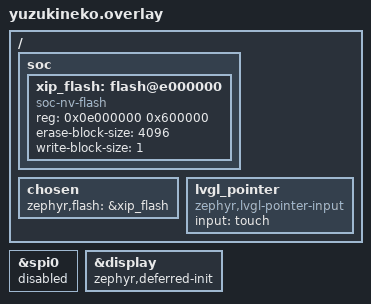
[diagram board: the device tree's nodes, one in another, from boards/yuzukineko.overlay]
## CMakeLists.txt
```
# SPDX-License-Identifier: Apache-2.0

cmake_minimum_required(VERSION 3.20.0)
# the emulator modules sit next to this application
list(APPEND ZEPHYR_EXTRA_MODULES ${CMAKE_CURRENT_SOURCE_DIR}/../mgba ${CMAKE_CURRENT_SOURCE_DIR}/../nes
	${CMAKE_CURRENT_SOURCE_DIR}/../aic8800)

find_package(Zephyr REQUIRED HINTS $ENV{ZEPHYR_BASE})
project(mp5_player)

# sources include each other as "core/cfg.h"; LVGL includes lv_rvv.h from its blend sources
zephyr_include_directories(src src/gfx)

# the start steps and the registries of the user interface are read only records that the
# modules register; the linker collects them
zephyr_linker_sources(SECTIONS src/core/sections-rom.ld)
zephyr_linker_sources(SECTIONS src/ui/sections-rom.ld)

target_sources(app PRIVATE src/main.c)
add_subdirectory(src/core)
add_subdirectory(src/ui)
add_subdirectory(src/gfx)
add_subdirectory(src/debug)
add_subdirectory(src/features/home)
add_subdirectory(src/features/files)
add_subdirectory(src/features/settings)
add_subdirectory(src/features/video)
add_subdirectory(src/features/photos)
add_subdirectory(src/features/games)
add_subdirectory(src/features/usbdisplay)
add_subdirectory(src/features/net)
```

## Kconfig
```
# SPDX-License-Identifier: Apache-2.0

mainmenu "MP5 player"

rsource "src/core/Kconfig"
rsource "src/gfx/Kconfig"
rsource "src/features/*/Kconfig"
rsource "src/debug/Kconfig"

source "Kconfig.zephyr"
```

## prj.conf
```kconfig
# the whole image runs from the flash window of the SPIF controller (see boards/yuzukineko.overlay)
CONFIG_XIP=y

CONFIG_SDHC=y
CONFIG_DISK_ACCESS=y
CONFIG_DISK_DRIVER_SDMMC=y
CONFIG_FILE_SYSTEM=y
CONFIG_FAT_FILESYSTEM_ELM=y
CONFIG_FS_FATFS_EXFAT=y
CONFIG_FS_FATFS_LFN=y
CONFIG_FS_FATFS_LFN_MODE_STACK=y
# the audio and the video thread read the same card, and the file browser does too
CONFIG_FS_FATFS_REENTRANT=y
CONFIG_LOG=y
CONFIG_LOG_PRINTK=n
CONFIG_PRINTK=y
CONFIG_SHELL=n
CONFIG_DEVMEM_SHELL=n
CONFIG_MAIN_STACK_SIZE=16384
# the malloc arena is a fixed size: with the MMU (MP5_GAMES_PAGED_ROM) the rest of the RAM is the
# page frames of the game ROM, and the buffers of the decoders and the display need the arena
CONFIG_COMMON_LIBC_MALLOC_ARENA_SIZE=8388608
CONFIG_HEAP_MEM_POOL_SIZE=196608
CONFIG_MAIN_THREAD_PRIORITY=8

# drivers the player does not use
CONFIG_G2D=n
CONFIG_ADC=n
CONFIG_SPI=n
CONFIG_MIPI_DBI=n
CONFIG_WDT_SUNXI=n
CONFIG_GPIO=y
CONFIG_FPU=y
CONFIG_FPU_SHARING=y

# the user interface: LVGL on the ARGB frame buffer plane, over the video plane
CONFIG_DISPLAY=y
CONFIG_DISPLAY_SUNXI_ARGB8888=y
CONFIG_LVGL=y
CONFIG_LV_COLOR_DEPTH_32=y
CONFIG_LV_Z_MEM_POOL_SIZE=262144
CONFIG_LV_Z_VDB_SIZE=15
CONFIG_LV_Z_SHELL=n
CONFIG_LV_USE_LABEL=y
CONFIG_LV_USE_BUTTON=y
CONFIG_LV_USE_SLIDER=y
CONFIG_LV_USE_ROLLER=y
CONFIG_LV_USE_LIST=y
CONFIG_LV_USE_IMAGE=y
CONFIG_LV_FONT_MONTSERRAT_14=y
CONFIG_LV_FONT_MONTSERRAT_16=y
CONFIG_LV_FONT_MONTSERRAT_20=y
CONFIG_LV_FONT_MONTSERRAT_24=y
CONFIG_LV_FONT_MONTSERRAT_28=y
CONFIG_LV_FONT_MONTSERRAT_48=y

# the touch events are handled above the thread of the user interface: a long redraw of the main
# thread must not make the input queue overflow
CONFIG_INPUT_THREAD_PRIORITY_OVERRIDE=y
CONFIG_INPUT_THREAD_PRIORITY=2
CONFIG_INPUT_QUEUE_MAX_MSGS=64
CONFIG_LV_Z_POINTER_INPUT_MSGQ_COUNT=32

# -Og is the default; the drawing code of LVGL and the decoders need the speed
CONFIG_SPEED_OPTIMIZATIONS=y

# the vector blends (src/gfx/lv_rvv.c) are included into the LVGL sources
CONFIG_LV_DRAW_SW_ASM_CUSTOM=y
CONFIG_LV_DRAW_SW_ASM_CUSTOM_INCLUDE="lv_rvv.h"

# the real time clock
CONFIG_RTC=y

CONFIG_NET_IPV6=n
CONFIG_LV_USE_SWITCH=y
CONFIG_LV_USE_KEYBOARD=y
CONFIG_LV_USE_TEXTAREA=y
CONFIG_THREAD_NAME=y
CONFIG_LV_Z_AUTO_INIT=n

# a card with no file system that can be read is never formatted by the player
CONFIG_FS_FATFS_MKFS=n
CONFIG_FS_FATFS_MOUNT_MKFS=n
```

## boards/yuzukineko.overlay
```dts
/*
 * MP5 runs in place from the flash: the image is linked into the memory window of the SPIF
 * controller, which the boot stub (SyterKit xip-boot) maps from the flash offset 0x8000 at
 * 0x0e000000. The window is 6 MiB, up to the end of the 16 MiB flash.
 */

/ {
	soc {
		xip_flash: flash@e000000 {
			compatible = "soc-nv-flash";
			reg = <0x0e000000 0x600000>;
			erase-block-size = <4096>;
			write-block-size = <1>;
		};
	};

	chosen {
		zephyr,flash = &xip_flash;
	};

	/* LVGL reads the GT967 touch panel as a pointer */
	lvgl_pointer {
		compatible = "zephyr,lvgl-pointer-input";
		input = <&touch>;
	};
};

/* spi0 uses the pins of the flash (PC0..PC5): switching them away would cut the window off */
&spi0 {
	status = "disabled";
};

/* the panel is brought up by the application in a thread of its own, in parallel with the rest of the start */
&display {
	zephyr,deferred-init;
};
```

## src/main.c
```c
/*
 * Copyright (c) 2026 Yuzuki Tsuru
 *
 * SPDX-License-Identifier: Apache-2.0
 */

/*
 * MP5: a small media player for the YuzukiNeko. A home screen with a clock leads to the video
 * player, the file browser, the photo viewer and the USB second screen. The user interface is
 * LVGL on the ARGB frame buffer plane; the video, the photos and the second screen go to the
 * video plane underneath. The whole image runs in place from the flash (XIP).
 *
 * main() only runs the start stages; what happens in them is registered by the modules with
 * MP5_INIT (core/app.h).
 */

#include <zephyr/kernel.h>
#include <zephyr/sys/printk.h>

#include "core/app.h"
#include "mp5.h"

int main(void)
{
	static const enum mp5_stage stages[] = {
		MP5_STAGE_EARLY, MP5_STAGE_STORAGE, MP5_STAGE_UI, MP5_STAGE_SERVICES,
	};

	printk("mp5: boot %u ms: main starts\n", k_uptime_get_32());
	for (int i = 0; i < ARRAY_SIZE(stages); i++) {
		if (mp5_run_stage(stages[i]) != 0) {
			printk("mp5: start failed in stage %d\n", stages[i]);
			return 0;
		}
	}
	ui_present();
	mp5_run_stage(MP5_STAGE_READY);
	ui_loop();

	return 0;
}
```

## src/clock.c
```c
/*
 * Copyright (c) 2026 Yuzuki Tsuru
 *
 * SPDX-License-Identifier: Apache-2.0
 */

/* A software clock: the board has no RTC, so the time counts from the build time */

#include <string.h>
#include <zephyr/kernel.h>

#include "mp5.h"

/* seconds since the epoch at uptime 0 */
static int64_t epoch_at_boot;
static bool initialised;

static int64_t days_from_civil(int y, int m, int d)
{
	int era, yoe, doy, doe;

	y -= m <= 2;
	era = (y >= 0 ? y : y - 399) / 400;
	yoe = y - era * 400;
	doy = (153 * (m + (m > 2 ? -3 : 9)) + 2) / 5 + d - 1;
	doe = yoe * 365 + yoe / 4 - yoe / 100 + doy;

	return (int64_t)era * 146097 + doe - 719468;
}

/* __DATE__ is "Oct 11 2026", __TIME__ is "11:39:00" */
static int64_t build_time(void)
{
	static const char months[] = "JanFebMarAprMayJunJulAugSepOctNovDec";
	const char *d = __DATE__, *t = __TIME__;
	int m = 1, day, year, hh, mm, ss;

	for (int i = 0; i < 12; i++) {
		if (strncmp(d, months + i * 3, 3) == 0) {
			m = i + 1;
		}
	}
	day = (d[4] == ' ' ? 0 : d[4] - '0') * 10 + (d[5] - '0');
	year = (d[7] - '0') * 1000 + (d[8] - '0') * 100 + (d[9] - '0') * 10 + (d[10] - '0');
	hh = (t[0] - '0') * 10 + (t[1] - '0');
	mm = (t[3] - '0') * 10 + (t[4] - '0');
	ss = (t[6] - '0') * 10 + (t[7] - '0');

	return days_from_civil(year, m, day) * 86400 + hh * 3600 + mm * 60 + ss;
}

static int64_t now_s(void)
{
	if (!initialised) {
		epoch_at_boot = build_time();
		initialised = true;
	}

	return epoch_at_boot + k_uptime_get() / 1000;
}

void clock_now(struct tm *tm)
{
	int64_t s = now_s();
	int64_t days = s / 86400;
	int sod = (int)(s % 86400);
	int z, era, doe, yoe, y, doy, mp, d, m;

	/* civil_from_days */
	z = (int)days + 719468;
	era = (z >= 0 ? z : z - 146096) / 146097;
	doe = z - era * 146097;
	yoe = (doe - doe / 1460 + doe / 36524 - doe / 146096) / 365;
	y = yoe + era * 400;
	doy = doe - (365 * yoe + yoe / 4 - yoe / 100);
	mp = (5 * doy + 2) / 153;
	d = doy - (153 * mp + 2) / 5 + 1;
	m = mp + (mp < 10 ? 3 : -9);
	y += m <= 2;

	memset(tm, 0, sizeof(*tm));
	tm->tm_year = y - 1900;
	tm->tm_mon = m - 1;
	tm->tm_mday = d;
	tm->tm_hour = sod / 3600;
	tm->tm_min = sod / 60 % 60;
	tm->tm_sec = sod % 60;
	tm->tm_wday = (int)((days % 7 + 11) % 7);	/* 1970-01-01 was a Thursday */
}

void clock_set(int hour, int minute)
{
	int64_t s = now_s();
	int64_t day_start = s - s % 86400;

	epoch_at_boot = day_start + hour * 3600 + minute * 60 - k_uptime_get() / 1000;
}
```

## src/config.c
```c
/*
 * Copyright (c) 2026 Yuzuki Tsuru
 *
 * SPDX-License-Identifier: Apache-2.0
 */

/*
 * The settings that stay across power cycles: a text file on the SD card with one "key value"
 * line per setting (the theme, the Wi-Fi network).
 */

#include <stdio.h>
#include <string.h>
#include <zephyr/fs/fs.h>
#include <zephyr/kernel.h>

#include "mp5.h"

#define CFG_FILE	"/SD:/.mp5_settings"
#define CFG_MAX		28
#define KEY_LEN		16
#define VAL_LEN		96

static struct {
	char key[KEY_LEN];
	char val[VAL_LEN];
} items[CFG_MAX];
static int count;
static K_MUTEX_DEFINE(lock);

static void save(void)
{
	struct fs_file_t f;
	char line[KEY_LEN + VAL_LEN + 4];

	if (!storage_ready()) {
		return;
	}
	fs_file_t_init(&f);
	if (fs_open(&f, CFG_FILE, FS_O_CREATE | FS_O_WRITE | FS_O_TRUNC) != 0) {
		return;
	}
	for (int i = 0; i < count; i++) {
		int n = snprintf(line, sizeof(line), "%s %s\n", items[i].key, items[i].val);

		if (fs_write(&f, line, n) < 0) {
			break;
		}
	}
	fs_close(&f);
}

void cfg_load(void)
{
	struct fs_file_t f;
	char buf[3072];
	ssize_t n;

	k_mutex_lock(&lock, K_FOREVER);
	count = 0;
	fs_file_t_init(&f);
	if (storage_ready() && fs_open(&f, CFG_FILE, FS_O_READ) == 0) {
		n = fs_read(&f, buf, sizeof(buf) - 1);
		fs_close(&f);
		if (n > 0) {
			char *line = buf, *next;

			buf[n] = '\0';
			for (; line != NULL && *line != '\0' && count < CFG_MAX; line = next) {
				char *sp;

				next = strchr(line, '\n');
				if (next != NULL) {
					*next++ = '\0';
				}
				sp = strchr(line, ' ');
				if (sp == NULL || sp == line || (sp - line) >= KEY_LEN) {
					continue;
				}
				*sp++ = '\0';
				strncpy(items[count].key, line, KEY_LEN - 1);
				strncpy(items[count].val, sp, VAL_LEN - 1);
				count++;
			}
		}
	}
	k_mutex_unlock(&lock);
}

const char *cfg_get(const char *key)
{
	const char *ret = NULL;

	k_mutex_lock(&lock, K_FOREVER);
	for (int i = 0; i < count; i++) {
		if (strcmp(items[i].key, key) == 0) {
			ret = items[i].val;
			break;
		}
	}
	k_mutex_unlock(&lock);

	return ret;
}

void cfg_set(const char *key, const char *value)
{
	int at = -1;

	k_mutex_lock(&lock, K_FOREVER);
	for (int i = 0; i < count; i++) {
		if (strcmp(items[i].key, key) == 0) {
			at = i;
			break;
		}
	}
	if (value == NULL) {
		if (at >= 0) {
			items[at] = items[count - 1];
			count--;
		}
	} else {
		if (at < 0 && count < CFG_MAX) {
			at = count++;
		}
		if (at >= 0) {
			strncpy(items[at].key, key, KEY_LEN - 1);
			items[at].key[KEY_LEN - 1] = '\0';
			strncpy(items[at].val, value, VAL_LEN - 1);
			items[at].val[VAL_LEN - 1] = '\0';
		}
	}
	save();
	k_mutex_unlock(&lock);
}
```

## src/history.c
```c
/*
 * Copyright (c) 2026 Yuzuki Tsuru
 *
 * SPDX-License-Identifier: Apache-2.0
 */

/*
 * The videos that were played last, with the position they were left at. The list is a text file
 * on the SD card, one line per video: "<position ms> <duration ms> <path>".
 */

#include <stdio.h>
#include <stdlib.h>
#include <string.h>
#include <zephyr/fs/fs.h>
#include <zephyr/kernel.h>
#include <zephyr/sys/printk.h>

#include "history.h"

#define HISTORY_FILE "/SD:/.mp5_recent"

static struct history_entry list[HISTORY_MAX];
static int count;
static bool loaded;

static void save(void)
{
	struct fs_file_t f;
	char line[HISTORY_PATH_MAX + 32];

	fs_file_t_init(&f);
	if (fs_open(&f, HISTORY_FILE, FS_O_CREATE | FS_O_WRITE | FS_O_TRUNC) != 0) {
		return;
	}
	for (int i = 0; i < count; i++) {
		int n = snprintf(line, sizeof(line), "%u %u %s\n", (unsigned)list[i].pos_ms,
				 (unsigned)list[i].dur_ms, list[i].path);

		if (fs_write(&f, line, n) < 0) {
			break;
		}
	}
	fs_close(&f);
}

void history_load(void)
{
	struct fs_file_t f;
	struct fs_dirent st;
	char *buf, *p, *end;

	count = 0;
	loaded = true;
	if (fs_stat(HISTORY_FILE, &st) != 0 || st.size == 0 || st.size > 16 * 1024) {
		return;
	}
	buf = malloc(st.size + 1);
	if (buf == NULL) {
		return;
	}
	fs_file_t_init(&f);
	if (fs_open(&f, HISTORY_FILE, FS_O_READ) != 0) {
		free(buf);
		return;
	}
	st.size = fs_read(&f, buf, st.size);
	fs_close(&f);
	buf[st.size > 0 ? st.size : 0] = '\0';

	for (p = buf; *p != '\0' && count < HISTORY_MAX; p = end) {
		unsigned long pos, dur;
		char *q;

		end = strchr(p, '\n');
		if (end != NULL) {
			*end++ = '\0';
		} else {
			end = p + strlen(p);
		}
		pos = strtoul(p, &q, 10);
		dur = strtoul(q, &q, 10);
		if (*q == ' ' && strlen(q + 1) < HISTORY_PATH_MAX) {
			strcpy(list[count].path, q + 1);
			list[count].pos_ms = pos;
			list[count].dur_ms = dur;
			count++;
		}
	}
	free(buf);
}

int history_count(void)
{
	if (!loaded) {
		history_load();
	}

	return count;
}

const struct history_entry *history_get(int index)
{
	return index >= 0 && index < history_count() ? &list[index] : NULL;
}

const struct history_entry *history_find(const char *path)
{
	for (int i = 0; i < history_count(); i++) {
		if (strcmp(list[i].path, path) == 0) {
			return &list[i];
		}
	}

	return NULL;
}

void history_update(const char *path, uint32_t pos_ms, uint32_t dur_ms)
{
	int at = -1;
	struct history_entry e;

	if (strlen(path) >= HISTORY_PATH_MAX) {
		return;
	}
	(void)history_count();
	for (int i = 0; i < count; i++) {
		if (strcmp(list[i].path, path) == 0) {
			at = i;
			break;
		}
	}
	if (at < 0) {
		at = count < HISTORY_MAX ? count++ : HISTORY_MAX - 1;
	}
	memmove(&list[1], &list[0], at * sizeof(list[0]));
	strcpy(e.path, path);
	e.pos_ms = pos_ms;
	e.dur_ms = dur_ms;
	list[0] = e;
	save();
}
 
```

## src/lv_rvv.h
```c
/*
 * Copyright (c) 2026 Yuzuki Tsuru
 *
 * SPDX-License-Identifier: Apache-2.0
 */

/*
 * Vector versions of the blend functions of the LVGL software renderer for the ARGB8888 target.
 * LVGL includes this file in its blend sources (LV_DRAW_SW_ASM_CUSTOM_INCLUDE); a hook that
 * returns LV_RESULT_INVALID leaves the work to the scalar code of LVGL, so a case that is not
 * handled here is still correct.
 */

#ifndef LV_RVV_H_
#define LV_RVV_H_

#include <stdbool.h>
#include <stddef.h>

#include "misc/lv_types.h"

#ifdef __cplusplus
extern "C" {
#endif

/** Switches the vector code on or off at run time (on by default); used by the self test */
void lv_rvv_enable(bool on);

/** Compares the vector blends with the scalar code of LVGL on random data; true when equal */
bool lv_rvv_selftest(void);

/* the return values are lv_result_t: LV_RESULT_OK when the blend was done, LV_RESULT_INVALID if not */
int lv_rvv_color_fill(lv_draw_sw_blend_fill_dsc_t *dsc);
int lv_rvv_color_opa(lv_draw_sw_blend_fill_dsc_t *dsc);
int lv_rvv_color_mask(lv_draw_sw_blend_fill_dsc_t *dsc);
int lv_rvv_color_mask_opa(lv_draw_sw_blend_fill_dsc_t *dsc);
int lv_rvv_argb_normal(lv_draw_sw_blend_image_dsc_t *dsc);
int lv_rvv_argb_opa(lv_draw_sw_blend_image_dsc_t *dsc);
int lv_rvv_argb_mask(lv_draw_sw_blend_image_dsc_t *dsc);
int lv_rvv_argb_mask_opa(lv_draw_sw_blend_image_dsc_t *dsc);

#define LV_DRAW_SW_COLOR_BLEND_TO_ARGB8888(dsc)				lv_rvv_color_fill(dsc)
#define LV_DRAW_SW_COLOR_BLEND_TO_ARGB8888_WITH_OPA(dsc)		lv_rvv_color_opa(dsc)
#define LV_DRAW_SW_COLOR_BLEND_TO_ARGB8888_WITH_MASK(dsc)		lv_rvv_color_mask(dsc)
#define LV_DRAW_SW_COLOR_BLEND_TO_ARGB8888_MIX_MASK_OPA(dsc)		lv_rvv_color_mask_opa(dsc)
#define LV_DRAW_SW_ARGB8888_BLEND_NORMAL_TO_ARGB8888(dsc)		lv_rvv_argb_normal(dsc)
#define LV_DRAW_SW_ARGB8888_BLEND_NORMAL_TO_ARGB8888_WITH_OPA(dsc)	lv_rvv_argb_opa(dsc)
#define LV_DRAW_SW_ARGB8888_BLEND_NORMAL_TO_ARGB8888_WITH_MASK(dsc)	lv_rvv_argb_mask(dsc)
#define LV_DRAW_SW_ARGB8888_BLEND_NORMAL_TO_ARGB8888_MIX_MASK_OPA(dsc)	lv_rvv_argb_mask_opa(dsc)

#ifdef __cplusplus
}
#endif

#endif /* LV_RVV_H_ */
```

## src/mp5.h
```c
/*
 * Copyright (c) 2026 Yuzuki Tsuru
 *
 * SPDX-License-Identifier: Apache-2.0
 */

#ifndef MP5_H_
#define MP5_H_

#include <lvgl.h>
#include <stdbool.h>
#include <stdint.h>
#include <time.h>

/* ---- palette ---------------------------------------------------------------------------- */

/* The colours of the user interface: they change with the theme (dark or light, and the accent) */
struct palette {
	uint32_t bg, surface, surface2, border, text, dim, accent, accent2, ok, warn, pink;
};

extern struct palette ui_pal;

#define C_BG		(ui_pal.bg)
#define C_SURFACE	(ui_pal.surface)
#define C_SURFACE2	(ui_pal.surface2)
#define C_BORDER	(ui_pal.border)
#define C_TEXT		(ui_pal.text)
#define C_DIM		(ui_pal.dim)
#define C_ACCENT	(ui_pal.accent)
#define C_ACCENT2	(ui_pal.accent2)
#define C_OK		(ui_pal.ok)
#define C_WARN		(ui_pal.warn)
#define C_PINK		(ui_pal.pink)

/** The theme: dark or light and one of the accent colours */
#define UI_ACCENTS	6
bool ui_theme_dark(void);
int ui_theme_accent(void);
const char *ui_theme_accent_name(int index);
uint32_t ui_theme_accent_color(int index);
/** Brightness of the backlight, 10..255 */
int ui_brightness(void);
/** Sets the brightness; @p save also writes it to the settings */
void ui_brightness_set(int value, bool save);

/** Sets the theme, saves it and builds the screens again */
void ui_theme_set(bool dark, int accent);

/* ---- settings kept on the card ---------------------------------------------------------- */

/** Reads the settings file of the card (call after the card is mounted) */
void cfg_load(void);
/** The value of a key, NULL when it is not set */
const char *cfg_get(const char *key);
/** Sets a key (NULL deletes it) and writes the file */
void cfg_set(const char *key, const char *value);

/* ---- screens ---------------------------------------------------------------------------- */

enum screen_id {
	SCR_HOME,
	SCR_FILES,
	SCR_PHOTOS,
	SCR_PLAYER,
	SCR_USB,
	SCR_RECENT,
	SCR_GAME,
	SCR_SETTINGS,
	SCR_WIFI,
	SCR_COUNT,
};

/** A plain screen in the background colour; transparent for the ones that show the video */
lv_obj_t *ui_screen_new(bool transparent);

/** A round, filled button with a symbol, used by the bars of the screens */
lv_obj_t *ui_icon_button(lv_obj_t *parent, const char *symbol, int32_t size);

/** A title bar with a back button and a title, at the top of @p parent */
lv_obj_t *ui_title_bar(lv_obj_t *parent, const char *title, lv_event_cb_t on_back);

/** The first picture, then the panel on; and the loop of the user interface thread */
void ui_present(void);
void ui_loop(void);

/** Shows another screen */
void ui_goto(enum screen_id id);

/** The screens register themselves with these (ui.c calls them when the screen is shown) */
struct screen_ops {
	lv_obj_t *(*create)(void);
	void (*enter)(void *arg);
	void (*leave)(void);
};

void ui_register(enum screen_id id, const struct screen_ops *ops);
void ui_goto_arg(enum screen_id id, void *arg);

/** Plays a video; the back button of the player returns to @p from (SCR_FILES or SCR_RECENT) */
void ui_player_open(const char *path, enum screen_id from);

/** What the file browser lists besides the folders */
enum files_filter {
	FILES_ALL,
	FILES_NES,	/**< .nes */
	FILES_GB,	/**< .gb .gbc .gba */
	FILES_VIDEO,	/**< .mp4 .h264 .264 */
	FILES_PHOTO,	/**< .jpg .jpeg .png */
};

/** Opens the file browser in @p dir (NULL: the root of the card) listing only @p filter */
void ui_files_open(const char *dir, enum files_filter filter);

/** The dialog that sets the time of day; used by the home and the settings screen */
void ui_set_time_dialog(void);

/** Starts a game (.nes .gb .gbc .gba); the cross of the game screen returns to @p from */
void ui_game_open(const char *path, enum screen_id from);

/** Case blind comparison of file names */
int ui_name_cmp(const char *a, const char *b);

/** True for the file names of photos (.jpg .jpeg .png) */
bool ui_photo_ext(const char *name);

/** True for the file names of games */
bool ui_game_ext(const char *name);

extern const struct screen_ops home_ops;
extern const struct screen_ops files_ops;
extern const struct screen_ops recent_ops;
extern const struct screen_ops game_ops;
extern const struct screen_ops settings_ops;
extern const struct screen_ops wifi_ops;
extern const struct screen_ops photos_ops;
extern const struct screen_ops usb_ops;
extern const struct screen_ops player_ops;

/** Raises the CPU clock to CONFIG_SAMPLE_MP5_CPU_MHZ, each step checked */
void cpu_clock_setup(void);

/* ---- network ---- */

/** One line about the Wi-Fi link and about the last time from the network, for the settings */
void app_net_status(char *buf, size_t size);
void app_net_sync_status(char *buf, size_t size);
/** Asks the network for the time and sets the clock with the answer */
void app_net_sync_time(void);
/** One line about Bluetooth: ready, or the device that is connected */
void bt_status(char *buf, size_t size);
/** True when a device is connected over Bluetooth */
bool bt_connected(void);

struct net_ap {
	char ssid[33];
	int8_t rssi;
	bool secured;
};

/** Starts a scan; the results come in while it runs */
void app_net_scan(void);
bool app_net_scanning(void);
/** Copies the access points found so far, strongest first; returns how many */
int app_net_scan_results(struct net_ap *out, int max);
/** The password saved for a network that was joined before; false when there is none */
bool app_net_saved_psk(const char *ssid, char *psk, size_t size);
/** Joins a network (psk may be empty for an open one) and saves it */
void app_net_connect(const char *ssid, const char *psk);
void app_net_disconnect(void);
bool app_net_connected(void);
/** True when the board has a Wi-Fi module that answered */
bool app_net_available(void);

/* ---- statistics, printed when they happen ---- */

void ui_stats_init(void);
void ui_stats_scroll_begin(const char *name);
void ui_stats_scroll_end(void);
void ui_stats_page_begin(const char *name);
void ui_stats_page_set_up(uint32_t us);
void ui_stats_scroll_summary(void);

/* ---- clock ------------------------------------------------------------------------------ */

/** The date and the time of day, from the real time clock */
void clock_now(struct tm *tm);
void clock_set(int hour, int minute);
/** Sets the date and the time (year since 1900, month 0..11) */
void clock_set_tm(const struct tm *tm);
/** False when the board has no usable real time clock */
bool clock_valid(void);

#include "core/storage.h"

#endif /* MP5_H_ */
```

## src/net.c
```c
/*
 * Copyright (c) 2026 Yuzuki Tsuru
 *
 * SPDX-License-Identifier: Apache-2.0
 */

/*
 * The network of the player: the Wi-Fi link of the AIC8800 chip (scan, join, address by DHCP), the
 * time of day from an NTP server, and the Bluetooth link of the same chip (only the state of the
 * connection is shown). Everything that waits runs in one worker thread; the user interface asks
 * for state and gives commands.
 */

#include <stdio.h>
#include <stdlib.h>
#include <string.h>
#include <time.h>

#include <zephyr/bluetooth/bluetooth.h>
#include <zephyr/fs/fs.h>
#include <zephyr/bluetooth/conn.h>
#include <zephyr/kernel.h>
#include <zephyr/net/net_if.h>
#include <zephyr/net/net_mgmt.h>
#include <zephyr/net/sntp.h>
#include <zephyr/net/wifi_mgmt.h>
#include <zephyr/sys/printk.h>

#include "mp5.h"

#define MAX_APS		24
#define CONNECT_WAIT_S	25
#define DHCP_WAIT_S	20
#define SYNC_RETRIES	3

enum link_state {
	LINK_NONE,		/* no module */
	LINK_STARTING,
	LINK_IDLE,		/* module ready, no network joined */
	LINK_SCANNING,
	LINK_CONNECTING,
	LINK_CONNECTED,		/* joined, waiting for the address */
	LINK_ONLINE,		/* has an address */
	LINK_FAILED,
};

enum command { CMD_SCAN, CMD_CONNECT, CMD_DISCONNECT, CMD_SYNC };

struct request {
	enum command cmd;
	char ssid[33];
	char psk[65];
};

K_MSGQ_DEFINE(requests, sizeof(struct request), 4, 4);
K_THREAD_STACK_DEFINE(net_stack, 6144);
static struct k_thread net_thread;

static struct k_mutex lock;
static volatile enum link_state link = LINK_STARTING;
static char ssid_now[33];
static char addr_now[NET_IPV4_ADDR_LEN];
static char fail_text[40];
static struct net_ap aps[MAX_APS];
static int ap_count;
static char sync_text[48] = "Not synced yet";
static bool sync_pending;

static struct net_mgmt_event_callback wifi_cb, ipv4_cb;
static K_SEM_DEFINE(scan_done, 0, 1);
static K_SEM_DEFINE(connect_done, 0, 1);
static K_SEM_DEFINE(got_ip, 0, 1);
static int connect_status;

/* ---- events ---------------------------------------------------------------------------- */

static void ap_add(const struct wifi_scan_result *r)
{
	int at = -1;

	k_mutex_lock(&lock, K_FOREVER);
	for (int i = 0; i < ap_count; i++) {
		if (strlen(aps[i].ssid) == r->ssid_length &&
		    memcmp(aps[i].ssid, r->ssid, r->ssid_length) == 0) {
			at = i;
			break;
		}
	}
	if (at < 0 && ap_count < MAX_APS && r->ssid_length > 0) {
		at = ap_count++;
		memcpy(aps[at].ssid, r->ssid, r->ssid_length);
		aps[at].ssid[r->ssid_length] = '\0';
		aps[at].rssi = -128;
	}
	if (at >= 0 && r->rssi > aps[at].rssi) {
		aps[at].rssi = r->rssi;
		aps[at].secured = r->security != WIFI_SECURITY_TYPE_NONE;
	}
	k_mutex_unlock(&lock);
}

static void wifi_event(struct net_mgmt_event_callback *cb, uint64_t event, struct net_if *iface)
{
	switch (event) {
	case NET_EVENT_WIFI_SCAN_RESULT:
		ap_add(cb->info);
		break;
	case NET_EVENT_WIFI_SCAN_DONE:
		k_sem_give(&scan_done);
		break;
	case NET_EVENT_WIFI_CONNECT_RESULT:
		connect_status = ((const struct wifi_status *)cb->info)->status;
		k_sem_give(&connect_done);
		break;
	case NET_EVENT_WIFI_DISCONNECT_RESULT:
		if (link == LINK_CONNECTED || link == LINK_ONLINE) {
			link = LINK_IDLE;
		}
		break;
	}
}

static void ipv4_event(struct net_mgmt_event_callback *cb, uint64_t event, struct net_if *iface)
{
	if (event == NET_EVENT_IPV4_ADDR_ADD) {
		k_mutex_lock(&lock, K_FOREVER);
		net_addr_ntop(AF_INET, &iface->config.ip.ipv4->unicast[0].ipv4.address.in_addr,
			      addr_now, sizeof(addr_now));
		k_mutex_unlock(&lock);
		k_sem_give(&got_ip);
	}
}

/* ---- time from the network ------------------------------------------------------------- */

/* days since 1970 to a civil date (proleptic Gregorian) */
static void civil_from_days(int64_t z, int *y, int *m, int *d)
{
	int64_t era, doe, yoe, doy, mp;

	z += 719468;
	era = (z >= 0 ? z : z - 146096) / 146097;
	doe = z - era * 146097;
	yoe = (doe - doe / 1460 + doe / 36524 - doe / 146096) / 365;
	doy = doe - (365 * yoe + yoe / 4 - yoe / 100);
	mp = (5 * doy + 2) / 153;
	*d = doy - (153 * mp + 2) / 5 + 1;
	*m = mp < 10 ? mp + 3 : mp - 9;
	*y = yoe + era * 400 + (*m <= 2);
}

static void clock_from_unix(int64_t unix_s)
{
	int64_t local = unix_s + (int64_t)CONFIG_SAMPLE_MP5_UTC_OFFSET_MIN * 60;
	int64_t days = local / 86400;
	int sec = local % 86400, y, m, d;
	struct tm tm = {0};

	civil_from_days(days, &y, &m, &d);
	tm.tm_year = y - 1900;
	tm.tm_mon = m - 1;
	tm.tm_mday = d;
	tm.tm_hour = sec / 3600;
	tm.tm_min = sec / 60 % 60;
	tm.tm_sec = sec % 60;
	{
		struct tm before;

		clock_now(&before);
		printk("net: clock was %04d-%02d-%02d %02d:%02d:%02d, network says %04d-%02d-%02d "
		       "%02d:%02d:%02d\n", before.tm_year + 1900, before.tm_mon + 1, before.tm_mday,
		       before.tm_hour, before.tm_min, before.tm_sec, y, m, d, tm.tm_hour, tm.tm_min,
		       tm.tm_sec);
	}
	clock_set_tm(&tm);
	{
		struct tm after;

		clock_now(&after);
		printk("net: clock now %04d-%02d-%02d %02d:%02d:%02d\n", after.tm_year + 1900,
		       after.tm_mon + 1, after.tm_mday, after.tm_hour, after.tm_min, after.tm_sec);
	}
	k_mutex_lock(&lock, K_FOREVER);
	snprintf(sync_text, sizeof(sync_text), "Synced %04d-%02d-%02d %02d:%02d", y, m, d,
		 tm.tm_hour, tm.tm_min);
	k_mutex_unlock(&lock);
}

static bool time_sync(void)
{
	static const char *const servers[] = {CONFIG_SAMPLE_MP5_NTP_SERVER, "cn.pool.ntp.org",
					      "pool.ntp.org"};
	struct sntp_time ts;

	for (int i = 0; i < ARRAY_SIZE(servers); i++) {
		for (int n = 0; n < SYNC_RETRIES; n++) {
			int ret = sntp_simple(servers[i], 3000, &ts);

			if (ret == 0) {
				printk("net: time from %s: %llu\n", servers[i],
				       (unsigned long long)ts.seconds);
				clock_from_unix((int64_t)ts.seconds);
				return true;
			}
			printk("net: sntp %s: %d\n", servers[i], ret);
			k_msleep(500);
		}
	}
	k_mutex_lock(&lock, K_FOREVER);
	snprintf(sync_text, sizeof(sync_text), "No answer from the time server");
	k_mutex_unlock(&lock);

	return false;
}

/* ---- Wi-Fi commands -------------------------------------------------------------------- */

static void fail(const char *text)
{
	k_mutex_lock(&lock, K_FOREVER);
	snprintf(fail_text, sizeof(fail_text), "%s", text);
	k_mutex_unlock(&lock);
	link = LINK_FAILED;
}

static void do_scan(struct net_if *iface)
{
	enum link_state before = link;

	k_mutex_lock(&lock, K_FOREVER);
	ap_count = 0;
	k_mutex_unlock(&lock);
	link = LINK_SCANNING;
	k_sem_reset(&scan_done);
	if (net_mgmt(NET_REQUEST_WIFI_SCAN, iface, NULL, 0) != 0) {
		fail("Scan request failed");
		return;
	}
	if (k_sem_take(&scan_done, K_SECONDS(20)) != 0) {
		printk("net: scan timed out\n");
	}
	link = before == LINK_SCANNING ? LINK_IDLE : before;
}

static void do_connect(struct net_if *iface, const char *ssid, const char *psk)
{
	struct wifi_connect_req_params p = {
		.ssid = ssid,
		.ssid_length = strlen(ssid),
		.psk = psk,
		.psk_length = strlen(psk),
		.security = strlen(psk) ? WIFI_SECURITY_TYPE_PSK : WIFI_SECURITY_TYPE_NONE,
		.channel = WIFI_CHANNEL_ANY,
		.band = WIFI_FREQ_BAND_UNKNOWN,
	};

	k_mutex_lock(&lock, K_FOREVER);
	snprintf(ssid_now, sizeof(ssid_now), "%s", ssid);
	k_mutex_unlock(&lock);
	link = LINK_CONNECTING;
	k_sem_reset(&connect_done);
	k_sem_reset(&got_ip);
	if (net_mgmt(NET_REQUEST_WIFI_CONNECT, iface, &p, sizeof(p)) != 0) {
		fail("Connect request failed");
		return;
	}
	if (k_sem_take(&connect_done, K_SECONDS(CONNECT_WAIT_S)) != 0 || connect_status != 0) {
		net_mgmt(NET_REQUEST_WIFI_DISCONNECT, iface, NULL, 0);
		fail(connect_status != 0 ? "Wrong password or no answer" : "No answer from the network");
		return;
	}
	link = LINK_CONNECTED;
	if (k_sem_take(&got_ip, K_SECONDS(DHCP_WAIT_S)) != 0) {
		fail("No address from DHCP");
		return;
	}
	link = LINK_ONLINE;
	cfg_set("wifi_ssid", ssid);
	cfg_set("wifi_psk", psk);
	time_sync();
}

/* the network on the card: /SD:/wifi.cfg, the name on the first line, the password on the second */
static void wifi_cfg_read(char *ssid, size_t ssid_size, char *psk, size_t psk_size)
{
	struct fs_file_t f;
	char buf[128];
	ssize_t n;
	char *nl;

	fs_file_t_init(&f);
	if (!storage_ready() || fs_open(&f, "/SD:/wifi.cfg", FS_O_READ) != 0) {
		return;
	}
	n = fs_read(&f, buf, sizeof(buf) - 1);
	fs_close(&f);
	if (n <= 0) {
		return;
	}
	buf[n] = '\0';
	nl = strchr(buf, '\n');
	if (nl != NULL) {
		*nl++ = '\0';
	}
	for (char *e = buf + strlen(buf); e > buf && (e[-1] == '\r' || e[-1] == ' '); e--) {
		e[-1] = '\0';
	}
	snprintf(ssid, ssid_size, "%s", buf);
	if (nl != NULL) {
		char *end = strchr(nl, '\n');

		if (end != NULL) {
			*end = '\0';
		}
		for (char *e = nl + strlen(nl); e > nl && (e[-1] == '\r'); e--) {
			e[-1] = '\0';
		}
		snprintf(psk, psk_size, "%s", nl);
	}
	printk("net: network %s from the card\n", ssid);
}

static void net_main(void *a, void *b, void *c)
{
	struct net_if *iface = NULL;
	struct request req;
	char saved_ssid[33] = "", saved_psk[65] = "";
	const char *v;

	/* the chip starts together with the system, the interface shows up when it answers */
	for (int i = 0; i < 100 && iface == NULL; i++) {
		iface = net_if_get_first_wifi();
		if (iface == NULL) {
			k_msleep(100);
		}
	}
	if (iface == NULL) {
		link = LINK_NONE;
		return;
	}
	net_mgmt_init_event_callback(&wifi_cb, wifi_event,
				     NET_EVENT_WIFI_SCAN_RESULT | NET_EVENT_WIFI_SCAN_DONE |
				     NET_EVENT_WIFI_CONNECT_RESULT |
				     NET_EVENT_WIFI_DISCONNECT_RESULT);
	net_mgmt_add_event_callback(&wifi_cb);
	net_mgmt_init_event_callback(&ipv4_cb, ipv4_event, NET_EVENT_IPV4_ADDR_ADD);
	net_mgmt_add_event_callback(&ipv4_cb);
	k_sleep(K_SECONDS(1));
	link = LINK_IDLE;

	/* copies: connecting saves the network again in the same place */
	v = cfg_get("wifi_ssid");
	if (v != NULL) {
		snprintf(saved_ssid, sizeof(saved_ssid), "%s", v);
	}
	v = cfg_get("wifi_psk");
	if (v != NULL) {
		snprintf(saved_psk, sizeof(saved_psk), "%s", v);
	}
	if (saved_ssid[0] == '\0') {
		wifi_cfg_read(saved_ssid, sizeof(saved_ssid), saved_psk, sizeof(saved_psk));
	}
	if (saved_ssid[0] != '\0') {
		printk("net: joining %s\n", saved_ssid);
		do_connect(iface, saved_ssid, saved_psk);
		printk("net: link state %d (%s)\n", (int)link, addr_now);
	}

	for (;;) {
		if (k_msgq_get(&requests, &req, K_FOREVER) != 0) {
			continue;
		}
		switch (req.cmd) {
		case CMD_SCAN:
			do_scan(iface);
			break;
		case CMD_CONNECT:
			do_connect(iface, req.ssid, req.psk);
			break;
		case CMD_DISCONNECT:
			net_mgmt(NET_REQUEST_WIFI_DISCONNECT, iface, NULL, 0);
			cfg_set("wifi_ssid", NULL);
			cfg_set("wifi_psk", NULL);
			link = LINK_IDLE;
			break;
		case CMD_SYNC:
			if (link == LINK_ONLINE) {
				time_sync();
			}
			sync_pending = false;
			break;
		}
	}
}

/* ---- Bluetooth ------------------------------------------------------------------------- */

static struct bt_conn *bt_peer;
static char bt_peer_text[BT_ADDR_LE_STR_LEN];
static enum { BT_OFF, BT_STARTING, BT_READY, BT_LINKED, BT_FAILED } bt_state = BT_OFF;

static const struct bt_data adv_data[] = {
	BT_DATA_BYTES(BT_DATA_FLAGS, (BT_LE_AD_GENERAL | BT_LE_AD_NO_BREDR)),
	BT_DATA(BT_DATA_NAME_COMPLETE, CONFIG_BT_DEVICE_NAME, sizeof(CONFIG_BT_DEVICE_NAME) - 1),
};

static void adv_start(void)
{
	int err = bt_le_adv_start(BT_LE_ADV_CONN_FAST_1, adv_data, ARRAY_SIZE(adv_data), NULL, 0);

	if (err != 0 && err != -EALREADY) {
		printk("bt: advertising failed: %d\n", err);
	}
}

static void bt_connected_cb(struct bt_conn *conn, uint8_t err)
{
	if (err != 0) {
		return;
	}
	if (bt_peer == NULL) {
		bt_peer = bt_conn_ref(conn);
	}
	k_mutex_lock(&lock, K_FOREVER);
	bt_addr_le_to_str(bt_conn_get_dst(conn), bt_peer_text, sizeof(bt_peer_text));
	k_mutex_unlock(&lock);
	bt_state = BT_LINKED;
	printk("bt: connected %s\n", bt_peer_text);
}

static void bt_disconnected_cb(struct bt_conn *conn, uint8_t reason)
{
	if (bt_peer != NULL) {
		bt_conn_unref(bt_peer);
		bt_peer = NULL;
	}
	bt_state = BT_READY;
	printk("bt: disconnected (%u)\n", reason);
	adv_start();
}

BT_CONN_CB_DEFINE(bt_conn_cbs) = {
	.connected = bt_connected_cb,
	.disconnected = bt_disconnected_cb,
};

static void bt_main(void *a, void *b, void *c)
{
	int err;

	bt_state = BT_STARTING;
	err = bt_enable(NULL);
	if (err != 0) {
		printk("bt: enable failed: %d\n", err);
		bt_state = BT_FAILED;
		return;
	}
	bt_state = BT_READY;
	adv_start();
}

K_THREAD_STACK_DEFINE(bt_stack, 4096);
static struct k_thread bt_thread;

/* ---- interface for the user interface -------------------------------------------------- */

void app_net_init(void)
{
	k_mutex_init(&lock);
	k_thread_create(&net_thread, net_stack, K_THREAD_STACK_SIZEOF(net_stack), net_main, NULL, NULL,
			NULL, 12, 0, K_NO_WAIT);
	k_thread_name_set(&net_thread, "net");
	k_thread_create(&bt_thread, bt_stack, K_THREAD_STACK_SIZEOF(bt_stack), bt_main, NULL, NULL,
			NULL, 12, 0, K_MSEC(3500));
	k_thread_name_set(&bt_thread, "bt");
}

static void put(const struct request *r)
{
	if (k_msgq_put(&requests, r, K_NO_WAIT) != 0) {
		printk("net: busy\n");
	}
}

void app_net_status(char *buf, size_t size)
{
	k_mutex_lock(&lock, K_FOREVER);
	switch (link) {
	case LINK_NONE:
		snprintf(buf, size, "No Wi-Fi module found");
		break;
	case LINK_STARTING:
		snprintf(buf, size, "Starting");
		break;
	case LINK_IDLE:
		snprintf(buf, size, "Not connected");
		break;
	case LINK_SCANNING:
		snprintf(buf, size, "Scanning");
		break;
	case LINK_CONNECTING:
		snprintf(buf, size, "Connecting to %s", ssid_now);
		break;
	case LINK_CONNECTED:
		snprintf(buf, size, "%s, waiting for an address", ssid_now);
		break;
	case LINK_ONLINE:
		snprintf(buf, size, "%s  %s", ssid_now, addr_now);
		break;
	case LINK_FAILED:
		snprintf(buf, size, "%s", fail_text);
		break;
	}
	k_mutex_unlock(&lock);
}

void app_net_sync_status(char *buf, size_t size)
{
	k_mutex_lock(&lock, K_FOREVER);
	if (sync_pending) {
		snprintf(buf, size, "Asking the time server");
	} else if (link != LINK_ONLINE && strncmp(sync_text, "Synced", 6) != 0) {
		snprintf(buf, size, "Needs a Wi-Fi network");
	} else {
		snprintf(buf, size, "%s", sync_text);
	}
	k_mutex_unlock(&lock);
}

void app_net_sync_time(void)
{
	struct request r = {.cmd = CMD_SYNC};

	if (link != LINK_ONLINE) {
		return;
	}
	sync_pending = true;
	put(&r);
}

void bt_status(char *buf, size_t size)
{
	k_mutex_lock(&lock, K_FOREVER);
	switch (bt_state) {
	case BT_OFF:
	case BT_STARTING:
		snprintf(buf, size, "Starting");
		break;
	case BT_READY:
		snprintf(buf, size, "Ready as " CONFIG_BT_DEVICE_NAME);
		break;
	case BT_LINKED:
		snprintf(buf, size, "Connected  %s", bt_peer_text);
		break;
	case BT_FAILED:
		snprintf(buf, size, "Not available");
		break;
	}
	k_mutex_unlock(&lock);
}

bool bt_connected(void)
{
	return bt_state == BT_LINKED;
}

void app_net_scan(void)
{
	struct request r = {.cmd = CMD_SCAN};

	if (link == LINK_NONE || link == LINK_STARTING || link == LINK_SCANNING ||
	    link == LINK_CONNECTING) {
		return;
	}
	put(&r);
}

bool app_net_scanning(void)
{
	return link == LINK_SCANNING;
}

int app_net_scan_results(struct net_ap *out, int max)
{
	int n;

	k_mutex_lock(&lock, K_FOREVER);
	n = MIN(ap_count, max);
	memcpy(out, aps, n * sizeof(*out));
	k_mutex_unlock(&lock);
	/* strongest first */
	for (int i = 1; i < n; i++) {
		struct net_ap t = out[i];
		int j = i;

		while (j > 0 && out[j - 1].rssi < t.rssi) {
			out[j] = out[j - 1];
			j--;
		}
		out[j] = t;
	}

	return n;
}

void app_net_connect(const char *ssid, const char *psk)
{
	struct request r = {.cmd = CMD_CONNECT};

	snprintf(r.ssid, sizeof(r.ssid), "%s", ssid);
	snprintf(r.psk, sizeof(r.psk), "%s", psk);
	put(&r);
}

void app_net_disconnect(void)
{
	struct request r = {.cmd = CMD_DISCONNECT};

	put(&r);
}

bool app_net_connected(void)
{
	return link == LINK_ONLINE;
}

bool app_net_available(void)
{
	return link != LINK_NONE;
}
```

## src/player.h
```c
/*
 * Copyright (c) 2026 Yuzuki Tsuru
 *
 * SPDX-License-Identifier: Apache-2.0
 */

#ifndef MP5_PLAYER_H_
#define MP5_PLAYER_H_

#include <stdbool.h>
#include <stdint.h>

enum player_state {
	PLAYER_IDLE,		/**< nothing is open */
	PLAYER_PLAYING,
	PLAYER_PAUSED,
	PLAYER_ENDED,		/**< the end of the file was reached */
	PLAYER_ERROR,
};

struct player_info {
	uint32_t duration_ms;
	uint16_t width, height;
	bool has_audio;
};

/** Opens an MP4 file and starts playing it; the picture goes to the video plane */
int player_open(const char *path, struct player_info *info);

/** Stops, releases everything and takes the picture off the screen */
void player_close(void);

void player_play(void);
void player_pause(void);

/** Jumps to a position; a paused player shows the picture there and stays paused */
void player_seek(uint32_t ms);

enum player_state player_state(void);

/** Time stamp of the picture on the screen */
uint32_t player_position_ms(void);

/** Volume in percent, 0 is mute; may be called at any time */
void player_set_volume(int percent);
int player_volume(void);

#endif /* MP5_PLAYER_H_ */
```

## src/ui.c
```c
/*
 * Copyright (c) 2026 Yuzuki Tsuru
 *
 * SPDX-License-Identifier: Apache-2.0
 */

/* Shared pieces of the user interface: screen switching and the building blocks of the bars */

#include <zephyr/device.h>
#include <zephyr/drivers/display.h>
#include <zephyr/drivers/display/display_sunxi.h>
#include <zephyr/kernel.h>
#include <zephyr/sys/printk.h>

#include <stdio.h>
#include <stdlib.h>
#include <string.h>

#include "mp5.h"

static const struct screen_ops *screen_ops[SCR_COUNT];
static lv_obj_t *screens[SCR_COUNT];
static enum screen_id current = SCR_COUNT;
static const char *const screen_names[SCR_COUNT] = {
	[SCR_HOME] = "home", [SCR_FILES] = "files", [SCR_PHOTOS] = "photos",
	[SCR_PLAYER] = "player", [SCR_USB] = "usb", [SCR_RECENT] = "videos", [SCR_GAME] = "game", [SCR_SETTINGS] = "settings", [SCR_WIFI] = "wifi",
};

/* ---- theme ---------------------------------------------------------------------------- */

static const struct {
	const char *name;
	uint32_t accent, accent2;
} accents[UI_ACCENTS] = {
	{"Blue", 0x6C8CFF, 0x9B6CFF},
	{"Purple", 0x9B6CFF, 0xD443A8},
	{"Green", 0x3DDC97, 0x1FA97A},
	{"Orange", 0xFFB547, 0xF2822C},
	{"Pink", 0xFF6C9B, 0xD443A8},
	{"Red", 0xE5484D, 0xB02A37},
};

struct palette ui_pal = {
	.bg = 0x0B0F17, .surface = 0x151B28, .surface2 = 0x1F2740, .border = 0x2A3350,
	.text = 0xE8ECF4, .dim = 0x8B95A8, .accent = 0x6C8CFF, .accent2 = 0x9B6CFF,
	.ok = 0x3DDC97, .warn = 0xFFB547, .pink = 0xFF6C9B,
};
static bool theme_dark = true;
static int theme_accent;

bool ui_theme_dark(void)
{
	return theme_dark;
}

int ui_theme_accent(void)
{
	return theme_accent;
}

const char *ui_theme_accent_name(int index)
{
	return accents[CLAMP(index, 0, UI_ACCENTS - 1)].name;
}

uint32_t ui_theme_accent_color(int index)
{
	return accents[CLAMP(index, 0, UI_ACCENTS - 1)].accent;
}

static void palette_make(bool dark, int accent)
{
	theme_dark = dark;
	theme_accent = CLAMP(accent, 0, UI_ACCENTS - 1);
	if (dark) {
		ui_pal = (struct palette){
			.bg = 0x0B0F17, .surface = 0x151B28, .surface2 = 0x1F2740, .border = 0x2A3350,
			.text = 0xE8ECF4, .dim = 0x8B95A8,
			.ok = 0x3DDC97, .warn = 0xFFB547, .pink = 0xFF6C9B,
		};
	} else {
		ui_pal = (struct palette){
			.bg = 0xF1F3F9, .surface = 0xFFFFFF, .surface2 = 0xDFE5F2, .border = 0xCBD3E4,
			.text = 0x1B2233, .dim = 0x5C687F,
			.ok = 0x1FA97A, .warn = 0xD9830A, .pink = 0xE0457B,
		};
	}
	ui_pal.accent = accents[theme_accent].accent;
	ui_pal.accent2 = accents[theme_accent].accent2;
}

/* the saved theme, before the screens are built */
static void theme_load(void)
{
	const char *mode = cfg_get("theme");
	const char *acc = cfg_get("accent");

	palette_make(mode == NULL || strcmp(mode, "light") != 0, acc != NULL ? atoi(acc) : 0);
}

static int brightness = 255;

int ui_brightness(void)
{
	return brightness;
}

void ui_brightness_set(int value, bool save)
{
	static const struct device *const disp = DEVICE_DT_GET(DT_CHOSEN(zephyr_display));
	char buf[8];

	brightness = CLAMP(value, 10, 255);
	display_set_brightness(disp, brightness);
	if (save) {
		snprintf(buf, sizeof(buf), "%d", brightness);
		cfg_set("brightness", buf);
	}
}

static void ui_rebuild(void *unused);

void ui_theme_set(bool dark, int accent)
{
	char buf[8];

	palette_make(dark, accent);
	cfg_set("theme", dark ? "dark" : "light");
	snprintf(buf, sizeof(buf), "%d", theme_accent);
	cfg_set("accent", buf);
	/* the screen that asks is one of those to be deleted: do it after its event */
	lv_async_call(ui_rebuild, NULL);
}

lv_obj_t *ui_screen_new(bool transparent)
{
	lv_obj_t *s = lv_obj_create(NULL);

	lv_obj_remove_style_all(s);
	lv_obj_set_size(s, LV_PCT(100), LV_PCT(100));
	lv_obj_set_style_bg_color(s, lv_color_hex(C_BG), 0);
	lv_obj_set_style_bg_opa(s, transparent ? LV_OPA_TRANSP : LV_OPA_COVER, 0);
	lv_obj_remove_flag(s, LV_OBJ_FLAG_SCROLLABLE);

	return s;
}

lv_obj_t *ui_icon_button(lv_obj_t *parent, const char *symbol, int32_t size)
{
	lv_obj_t *b = lv_button_create(parent);
	lv_obj_t *l = lv_label_create(b);

	lv_obj_remove_style_all(b);
	lv_obj_set_size(b, size, size);
	lv_obj_set_style_radius(b, LV_RADIUS_CIRCLE, 0);
	lv_obj_set_style_bg_color(b, lv_color_hex(C_SURFACE2), 0);
	lv_obj_set_style_bg_opa(b, LV_OPA_COVER, 0);
	lv_obj_set_style_bg_color(b, lv_color_hex(C_ACCENT), LV_STATE_PRESSED);
	lv_obj_set_style_text_color(l, lv_color_hex(C_TEXT), 0);
	lv_obj_set_style_text_font(l, size >= 64 ? &lv_font_montserrat_28 : &lv_font_montserrat_20, 0);
	lv_label_set_text(l, symbol);
	lv_obj_center(l);

	return b;
}

lv_obj_t *ui_title_bar(lv_obj_t *parent, const char *title, lv_event_cb_t on_back)
{
	lv_obj_t *bar = lv_obj_create(parent);
	lv_obj_t *back = ui_icon_button(bar, LV_SYMBOL_LEFT, 56);
	lv_obj_t *t = lv_label_create(bar);

	lv_obj_remove_style_all(bar);
	lv_obj_set_size(bar, LV_PCT(100), 88);
	lv_obj_set_flex_flow(bar, LV_FLEX_FLOW_ROW);
	lv_obj_set_flex_align(bar, LV_FLEX_ALIGN_START, LV_FLEX_ALIGN_CENTER, LV_FLEX_ALIGN_CENTER);
	lv_obj_set_style_pad_column(bar, 20, 0);
	lv_obj_set_style_pad_hor(bar, 32, 0);
	lv_obj_add_event_cb(back, on_back, LV_EVENT_CLICKED, NULL);
	lv_obj_set_style_text_color(t, lv_color_hex(C_TEXT), 0);
	lv_obj_set_style_text_font(t, &lv_font_montserrat_28, 0);
	lv_label_set_text(t, title);

	return bar;
}

void ui_register(enum screen_id id, const struct screen_ops *ops)
{
	screen_ops[id] = ops;
}

/*
 * A new screen is drawn band by band into the frame buffer the display engine is scanning out,
 * which shows as a wipe from the top. The plane is kept off until the whole screen is drawn.
 */
static void screen_drawn(lv_event_t *e)
{
	static const struct device *const disp = DEVICE_DT_GET(DT_CHOSEN(zephyr_display));

	lv_display_remove_event_cb_with_user_data(lv_event_get_target(e), screen_drawn, NULL);
	display_sunxi_fb_enable(disp, true);
}

void ui_goto_arg(enum screen_id id, void *arg)
{
	static const struct device *const disp = DEVICE_DT_GET(DT_CHOSEN(zephyr_display));

	if (id >= SCR_COUNT || screen_ops[id] == NULL) {
		return;
	}
	if (screens[id] == NULL) {
		screens[id] = screen_ops[id]->create();
	}
	if (current < SCR_COUNT && screen_ops[current]->leave != NULL) {
		screen_ops[current]->leave();
	}
	current = id;
	ui_stats_page_begin(screen_names[id]);
	{
		uint32_t c0 = k_cycle_get_32();

		if (screen_ops[id]->enter != NULL) {
			screen_ops[id]->enter(arg);
		}
		ui_stats_page_set_up(k_cyc_to_us_floor32(k_cycle_get_32() - c0));
	}
	display_sunxi_fb_enable(disp, false);
	lv_display_add_event_cb(lv_display_get_default(), screen_drawn, LV_EVENT_REFR_READY, NULL);
	lv_screen_load(screens[id]);
}

void ui_goto(enum screen_id id)
{
	ui_goto_arg(id, NULL);
}

/* every screen is made again with the new colours */
static void ui_rebuild(void *unused)
{
	enum screen_id cur = current;
	bool made[SCR_COUNT];
	lv_obj_t *tmp = lv_obj_create(NULL);

	ARG_UNUSED(unused);
	if (cur < SCR_COUNT && screen_ops[cur]->leave != NULL) {
		screen_ops[cur]->leave();
	}
	lv_screen_load(tmp);
	for (int i = 0; i < SCR_COUNT; i++) {
		made[i] = screens[i] != NULL;
		if (made[i]) {
			lv_obj_delete(screens[i]);
			screens[i] = NULL;
		}
	}
	/* the screens that have timers of their own must have their objects again at once */
	for (int i = 0; i < SCR_COUNT; i++) {
		if (made[i]) {
			screens[i] = screen_ops[i]->create();
		}
	}
	current = SCR_COUNT;
	ui_goto(cur < SCR_COUNT ? cur : SCR_HOME);
	lv_obj_delete_async(tmp);
}

void ui_init(void)
{
	cfg_load();
	theme_load();
	{
		const char *b = cfg_get("brightness");

		if (b != NULL) {
			ui_brightness_set(atoi(b), false);
		}
	}
	ui_stats_init();
	ui_register(SCR_HOME, &home_ops);
	ui_register(SCR_FILES, &files_ops);
	ui_register(SCR_RECENT, &recent_ops);
	ui_register(SCR_GAME, &game_ops);
	ui_register(SCR_PHOTOS, &photos_ops);
	ui_register(SCR_USB, &usb_ops);
	ui_register(SCR_SETTINGS, &settings_ops);
	ui_register(SCR_WIFI, &wifi_ops);
	ui_register(SCR_PLAYER, &player_ops);
	ui_goto(SCR_HOME);
}
```
